VERSION ""

NS_ :

BS_:

BU_:

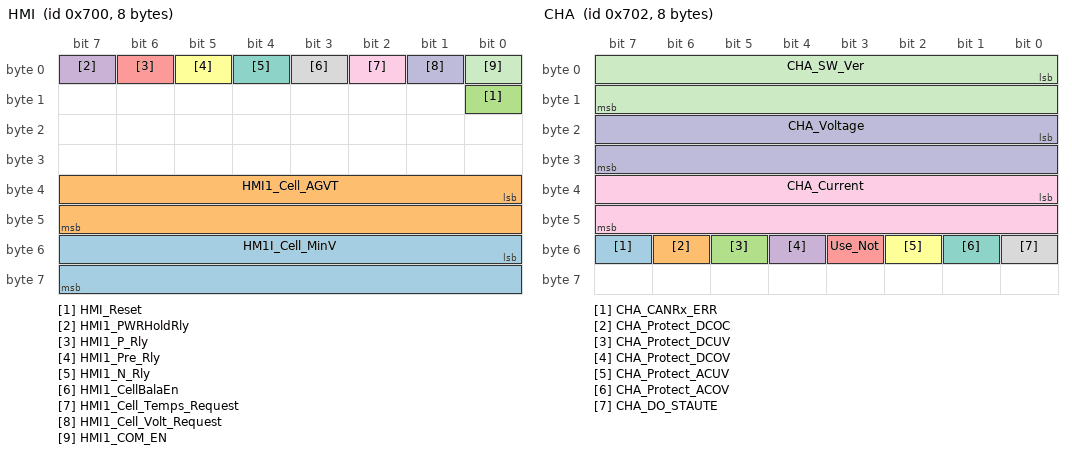
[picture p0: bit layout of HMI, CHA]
BO_ 1792 HMI: 8 Vector__XXX
 SG_ HM1I_Cell_MinV : 48|16@1+ (0.001,0.0) [0.0|4.5] "V" Vector__XXX
 SG_ HMI1_Cell_AGVT : 32|16@1+ (0.1,0.0) [-30.0|100.0] "deg" Vector__XXX
 SG_ HMI_Reset : 8|1@1+ (1.0,0.0) [0.0|1.0] "F" Vector__XXX
 SG_ HMI1_PWRHoldRly : 7|1@1+ (1.0,0.0) [0.0|1.0] "F" Vector__XXX
 SG_ HMI1_P_Rly : 6|1@1+ (1.0,0.0) [0.0|1.0] "F" Vector__XXX
 SG_ HMI1_Pre_Rly : 5|1@1+ (1.0,0.0) [0.0|1.0] "F" Vector__XXX
 SG_ HMI1_N_Rly : 4|1@1+ (1.0,0.0) [0.0|1.0] "F" Vector__XXX
 SG_ HMI1_CellBalaEn : 3|1@1+ (1.0,0.0) [0.0|1.0] "F" Vector__XXX
 SG_ HMI1_Cell_Temps_Request : 2|1@1+ (1.0,0.0) [0.0|1.0] "F" Vector__XXX
 SG_ HMI1_Cell_Volt_Request : 1|1@1+ (1.0,0.0) [0.0|1.0] "F" Vector__XXX
 SG_ HMI1_COM_EN : 0|1@1+ (1.0,0.0) [0.0|1.0] "F" Vector__XXX

BO_ 1794 CHA: 8 Vector__XXX
 SG_ CHA_CANRx_ERR : 55|1@1+ (1.0,0.0) [0.0|1.0] "F" Vector__XXX
 SG_ CHA_Protect_DCOC : 54|1@1+ (1.0,0.0) [0.0|1.0] "F" Vector__XXX
 SG_ CHA_Protect_DCUV : 53|1@1+ (1.0,0.0) [0.0|1.0] "F" Vector__XXX
 SG_ CHA_Protect_DCOV : 52|1@1+ (1.0,0.0) [0.0|1.0] "F" Vector__XXX
 SG_ Use_Not : 51|1@1+ (1.0,0.0) [0.0|1.0] "F" Vector__XXX
 SG_ CHA_Protect_ACUV : 50|1@1+ (1.0,0.0) [0.0|1.0] "F" Vector__XXX
 SG_ CHA_Protect_ACOV : 49|1@1+ (1.0,0.0) [0.0|1.0] "F" Vector__XXX
 SG_ CHA_DO_STAUTE : 48|1@1+ (1.0,0.0) [0.0|1.0] "F" Vector__XXX
 SG_ CHA_Current : 32|16@1- (0.1,0.0) [0.0|100.0] "A" Vector__XXX
 SG_ CHA_Voltage : 16|16@1+ (0.1,0.0) [40.0|100.0] "V" Vector__XXX
 SG_ CHA_SW_Ver : 0|16@1+ (0.1,0.0) [1.0|99.0] "VER" Vector__XXX

BO_ 1536 VCU_RE: 8 Vector__XXX
 SG_ VCU_BSAHldShutdown : 9|1@1+ (1.0,0.0) [0.0|1.0] "F" Vector__XXX
 SG_ VCU_BSAReset : 8|1@1+ (1.0,0.0) [0.0|1.0] "F" Vector__XXX

BO_ 812 CT_Sensor: 8 Sender
 SG_ CT_Sensor : 0|16@1+ (0.1,0.0) [-500.0|500.0] "A" Vector__XXX

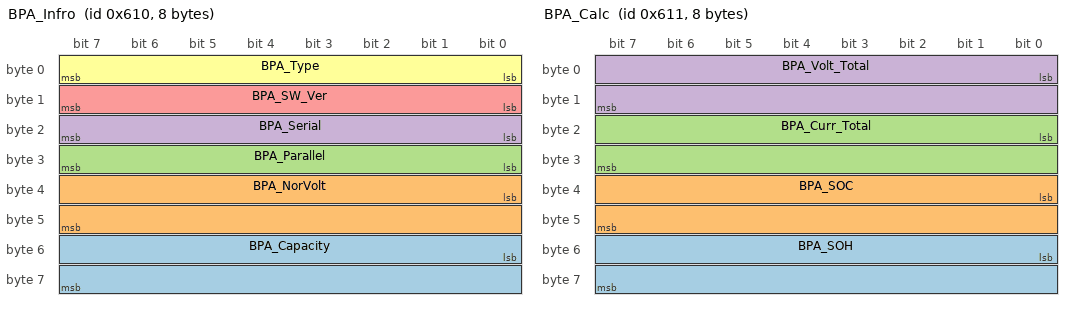
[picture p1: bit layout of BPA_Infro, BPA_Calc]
BO_ 1552 BPA_Infro: 8 Vector__XXX
 SG_ BPA_Capacity : 48|16@1+ (0.1,0.0) [0.0|500.0] "Ah" Vector__XXX
 SG_ BPA_NorVolt : 32|16@1+ (0.1,0.0) [0.0|900.0] "V" Vector__XXX
 SG_ BPA_Parallel : 24|8@1+ (1.0,0.0) [0.0|255.0] "P" Vector__XXX
 SG_ BPA_Serial : 16|8@1+ (1.0,0.0) [0.0|255.0] "S" Vector__XXX
 SG_ BPA_SW_Ver : 8|8@1+ (1.0,0.0) [0.0|255.0] "VER" Vector__XXX
 SG_ BPA_Type : 0|8@1+ (1.0,0.0) [0.0|255.0] "Type" Vector__XXX

BO_ 1553 BPA_Calc: 8 Vector__XXX
 SG_ BPA_SOH : 48|16@1+ (0.1,0.0) [0.0|100.0] "%" Vector__XXX
 SG_ BPA_SOC : 32|16@1+ (0.1,0.0) [0.0|100.0] "%" Vector__XXX
 SG_ BPA_Curr_Total : 16|16@1+ (0.1,0.0) [-500.0|500.0] "A" Vector__XXX
 SG_ BPA_Volt_Total : 0|16@1+ (0.1,0.0) [0.0|900.0] "V" Vector__XXX

BO_ 1554 BPA_State: 8 Vector__XXX
 SG_ Sys_HMIBalanceMode : 63|1@1+ (1.0,0.0) [0.0|1.0] "F" Vector__XXX
 SG_ Sys_HMICOMMode : 62|1@1+ (1.0,0.0) [0.0|1.0] "F" Vector__XXX
 SG_ Sys_IMDRegErr : 61|1@1+ (1.0,0.0) [0.0|1.0] "F" Vector__XXX
 SG_ Sys_ISOSPICOMERR : 60|1@1+ (1.0,0.0) [0.0|1.0] "F" Vector__XXX
 SG_ Sys_CANCOMERR : 59|1@1+ (1.0,0.0) [0.0|1.0] "F" Vector__XXX
 SG_ Sys_RlyERR : 58|1@1+ (1.0,0.0) [0.0|1.0] "F" Vector__XXX
 SG_ Sys_MSDERR : 57|1@1+ (1.0,0.0) [0.0|1.0] "F" Vector__XXX
 SG_ Sys_CellTempsOk : 56|1@1+ (1.0,0.0) [0.0|1.0] "F" Vector__XXX
 SG_ Sys_CellVoltOk : 55|1@1+ (1.0,0.0) [0.0|1.0] "F" Vector__XXX
 SG_ Sys_PwrHoldRlyDOStatus : 54|1@1+ (1.0,0.0) [0.0|1.0] "F" Vector__XXX
 SG_ Sys_PreRlyDOStatus : 53|1@1+ (1.0,0.0) [0.0|1.0] "F" Vector__XXX
 SG_ Sys_PRlyDOStatus : 52|1@1+ (1.0,0.0) [0.0|1.0] "F" Vector__XXX
 SG_ Sys_NRlyDOStatus : 51|1@1+ (1.0,0.0) [0.0|1.0] "F" Vector__XXX
 SG_ Sys_Prtct : 50|1@1+ (1.0,0.0) [0.0|1.0] "F" Vector__XXX
 SG_ Sys_Fault : 49|1@1+ (1.0,0.0) [0.0|1.0] "F" Vector__XXX
 SG_ Sys_Aalarm : 48|1@1+ (1.0,0.0) [0.0|1.0] "F" Vector__XXX
 SG_ Sys_DisCharMode : 47|1@1+ (1.0,0.0) [0.0|1.0] "F" Vector__XXX
 SG_ Sys_BalanceEn : 46|1@1+ (1.0,0.0) [0.0|1.0] "F" Vector__XXX
 SG_ Sys_BalaMode : 45|1@1+ (1.0,0.0) [0.0|1.0] "F" Vector__XXX
 SG_ Sys_SocMode : 44|1@1+ (1.0,0.0) [0.0|1.0] "F" Vector__XXX
 SG_ ChargerWakeUp : 43|1@1+ (1.0,0.0) [0.0|1.0] "F" Vector__XXX
 SG_ VCURlyWakeUp : 42|1@1+ (1.0,0.0) [0.0|1.0] "F" Vector__XXX
 SG_ CANCOMEnable : 41|1@1+ (1.0,0.0) [0.0|1.0] "F" Vector__XXX
 SG_ Sys_INITOK : 40|1@1+ (1.0,0.0) [0.0|1.0] "F" Vector__XXX
 SG_ Sys_SocSeqState : 38|2@1+ (1.0,0.0) [0.0|3.0] "s" Vector__XXX
 SG_ SyS_RlySeqState : 35|3@1+ (1.0,0.0) [0.0|7.0] "S" Vector__XXX
 SG_ Sys_SysSeqState : 32|3@1+ (1.0,0.0) [0.0|7.0] "S" Vector__XXX
 SG_ BPA_ChargerEn : 21|1@1+ (1.0,0.0) [0.0|1.0] "F" Vector__XXX
 SG_ BPA_MSD_AUX : 20|1@1+ (1.0,0.0) [0.0|1.0] "F" Vector__XXX
 SG_ BPA_PreChar_Rly : 19|1@1+ (1.0,0.0) [0.0|1.0] "F" Vector__XXX
 SG_ BPA_Pos_Rly : 18|1@1+ (1.0,0.0) [0.0|1.0] "F" Vector__XXX
 SG_ BPA_Neg_Rly : 17|1@1+ (1.0,0.0) [0.0|1.0] "F" Vector__XXX
 SG_ BPA_Balance : 16|1@1+ (1.0,0.0) [0.0|1.0] "F" Vector__XXX
 SG_ BPA_Protect_Status : 8|8@1+ (1.0,0.0) [0.0|5.0] "P" Vector__XXX
 SG_ BPA_Divice_Status : 0|8@1+ (1.0,0.0) [0.0|5.0] "S" Vector__XXX

BO_ 1555 BPA_ProtectState: 8 Vector__XXX
 SG_ BPA_Prtct_Charger_PwrErr : 53|1@1+ (1.0,0.0) [0.0|1.0] "F" Vector__XXX
 SG_ BPA_Prtct_Discharger_PwrErr : 52|1@1+ (1.0,0.0) [0.0|1.0] "F" Vector__XXX
 SG_ BPA_Prtct_CTCom_Err : 51|1@1+ (1.0,0.0) [0.0|1.0] "F" Vector__XXX
 SG_ BPA_Prtct_CharCom_Err : 50|1@1+ (1.0,0.0) [0.0|1.0] "F" Vector__XXX
 SG_ BPA_Prtct_VCUCom_Err : 49|1@1+ (1.0,0.0) [0.0|1.0] "F" Vector__XXX
 SG_ BPA_Prtct_ISOSPI_Err : 48|1@1+ (1.0,0.0) [0.0|1.0] "F" Vector__XXX
 SG_ BPA_Prtct_ISORESIS_Err : 47|1@1+ (1.0,0.0) [0.0|1.0] "F" Vector__XXX
 SG_ BPA_Prtct_MSD_Err : 46|1@1+ (1.0,0.0) [0.0|1.0] "F" Vector__XXX
 SG_ BPA_Prtct_Rly_Err : 45|1@1+ (1.0,0.0) [0.0|1.0] "F" Vector__XXX
 SG_ BPA_Prtct_Cell_UnbalT : 44|1@1+ (1.0,0.0) [0.0|1.0] "F" Vector__XXX
 SG_ BPA_Prtct_Cell_UT : 43|1@1+ (1.0,0.0) [0.0|1.0] "F" Vector__XXX
 SG_ BPA_Prtct_Cell_OT : 42|1@1+ (1.0,0.0) [0.0|1.0] "F" Vector__XXX
 SG_ BPA_Prtct_Cell_UnbalV : 41|1@1+ (1.0,0.0) [0.0|1.0] "F" Vector__XXX
 SG_ BPA_Prtct_Cell_UV : 40|1@1+ (1.0,0.0) [0.0|1.0] "F" Vector__XXX
 SG_ BPA_Prtct_Cell_OV : 39|1@1+ (1.0,0.0) [0.0|1.0] "F" Vector__XXX
 SG_ BPA_Prtct_UT : 38|1@1+ (1.0,0.0) [0.0|1.0] "F" Vector__XXX
 SG_ BPA_Prtct_OT : 37|1@1+ (1.0,0.0) [0.0|1.0] "F" Vector__XXX
 SG_ BPA_Prtct_UV : 36|1@1+ (1.0,0.0) [0.0|1.0] "F" Vector__XXX
 SG_ BPA_Prtct_OV : 35|1@1+ (1.0,0.0) [0.0|1.0] "F" Vector__XXX
 SG_ BPA_Prtct_SOC_Under : 34|1@1+ (1.0,0.0) [0.0|1.0] "F" Vector__XXX
 SG_ BPA_Prtct_SOC_Over : 33|1@1+ (1.0,0.0) [0.0|1.0] "F" Vector__XXX
 SG_ BPA_Prtct_OC : 32|1@1+ (1.0,0.0) [0.0|1.0] "" Vector__XXX
 SG_ BPA_FLT_Charger_UnBPAWR : 30|1@1+ (1.0,0.0) [0.0|1.0] "F" Vector__XXX
 SG_ BPA_FLT_Discharger_UnBPAWR : 29|1@1+ (1.0,0.0) [0.0|1.0] "F" Vector__XXX
 SG_ BSA_FLT_Cell_UnbalT : 28|1@1+ (1.0,0.0) [0.0|1.0] "F" Vector__XXX
 SG_ BPA_FLT_Cell_UT : 27|1@1+ (1.0,0.0) [0.0|1.0] "F" Vector__XXX
 SG_ BPA_FLT_Cell_OT : 26|1@1+ (1.0,0.0) [0.0|1.0] "F" Vector__XXX
 SG_ BPA_FLT_Cell_UnbalV : 25|1@1+ (1.0,0.0) [0.0|1.0] "F" Vector__XXX
 SG_ BPA_FLT_Cell_UV : 24|1@1+ (1.0,0.0) [0.0|1.0] "F" Vector__XXX
 SG_ BPA_FLT_Cell_OV : 23|1@1+ (1.0,0.0) [0.0|1.0] "F" Vector__XXX
 SG_ BPA_FLT_UT : 22|1@1+ (1.0,0.0) [0.0|1.0] "F" Vector__XXX
 SG_ BPA_FLT_OT : 21|1@1+ (1.0,0.0) [0.0|1.0] "F" Vector__XXX
 SG_ BPA_FLT_UV : 20|1@1+ (1.0,0.0) [0.0|1.0] "F" Vector__XXX
 SG_ BPA_FLT_OV : 19|1@1+ (1.0,0.0) [0.0|1.0] "F" Vector__XXX
 SG_ BPA_FLT_SOC_Under : 18|1@1+ (1.0,0.0) [0.0|1.0] "F" Vector__XXX
 SG_ BPA_FLT_SOC_Over : 17|1@1+ (1.0,0.0) [0.0|1.0] "F" Vector__XXX
 SG_ BPA_FLT_OC : 16|1@1+ (1.0,0.0) [0.0|1.0] "F" Vector__XXX
 SG_ BPA_Wn_Charger_UnBPAWR : 14|1@1+ (1.0,0.0) [0.0|1.0] "F" Vector__XXX
 SG_ BPA_Wn_Discharger_UnBPAWR : 13|1@1+ (1.0,0.0) [0.0|1.0] "F" Vector__XXX
 SG_ BSA_Wn_Cell_UnbalT : 12|1@1+ (1.0,0.0) [0.0|1.0] "F" Vector__XXX
 SG_ BPA_Wn_Cell_UT : 11|1@1+ (1.0,0.0) [0.0|1.0] "F" Vector__XXX
 SG_ BPA_Wn_Cell_OT : 10|1@1+ (1.0,0.0) [0.0|1.0] "F" Vector__XXX
 SG_ BPA_Wn_Cell_UnbalV : 9|1@1+ (1.0,0.0) [0.0|1.0] "F" Vector__XXX
 SG_ BPA_Wn_Cell_UV : 8|1@1+ (1.0,0.0) [0.0|1.0] "F" Vector__XXX
 SG_ BPA_Wn_Cell_OV : 7|1@1+ (1.0,0.0) [0.0|1.0] "F" Vector__XXX
 SG_ BPA_Wn_UT : 6|1@1+ (1.0,0.0) [0.0|1.0] "F" Vector__XXX
 SG_ BPA_Wn_OT : 5|1@1+ (1.0,0.0) [0.0|1.0] "F" Vector__XXX
 SG_ BPA_Wn_UV : 4|1@1+ (1.0,0.0) [0.0|1.0] "F" Vector__XXX
 SG_ BPA_Wn_OV : 3|1@1+ (1.0,0.0) [0.0|1.0] "F" Vector__XXX
 SG_ BPA_Wn_SOC_Under : 2|1@1+ (1.0,0.0) [0.0|1.0] "F" Vector__XXX
 SG_ BPA_Wn_SOC_Over : 1|1@1+ (1.0,0.0) [0.0|1.0] "F" Vector__XXX
 SG_ BPA_Wn_OC : 0|1@1+ (1.0,0.0) [0.0|1.0] "F" Vector__XXX

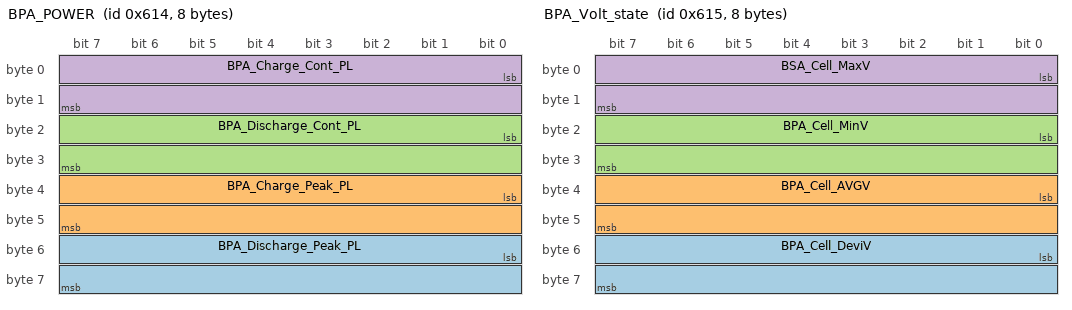
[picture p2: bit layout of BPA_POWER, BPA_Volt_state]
BO_ 1556 BPA_POWER: 8 Vector__XXX
 SG_ BPA_Discharge_Peak_PL : 48|16@1+ (0.1,0.0) [0.0|20.0] "kW" Vector__XXX
 SG_ BPA_Charge_Peak_PL : 32|16@1+ (0.1,0.0) [0.0|20.0] "kW" Vector__XXX
 SG_ BPA_Discharge_Cont_PL : 16|16@1+ (0.1,0.0) [0.0|20.0] "kW" Vector__XXX
 SG_ BPA_Charge_Cont_PL : 0|16@1+ (0.1,0.0) [0.0|20.0] "kW" Vector__XXX

BO_ 1557 BPA_Volt_state: 8 Vector__XXX
 SG_ BPA_Cell_DeviV : 48|16@1+ (1.0,0.0) [0.0|1000.0] "mV" Vector__XXX
 SG_ BPA_Cell_AVGV : 32|16@1+ (0.001,0.0) [0.0|4.5] "V" Vector__XXX
 SG_ BPA_Cell_MinV : 16|16@1+ (0.001,0.0) [0.0|4.5] "V" Vector__XXX
 SG_ BSA_Cell_MaxV : 0|16@1+ (0.001,0.0) [0.0|4.5] "V" Vector__XXX

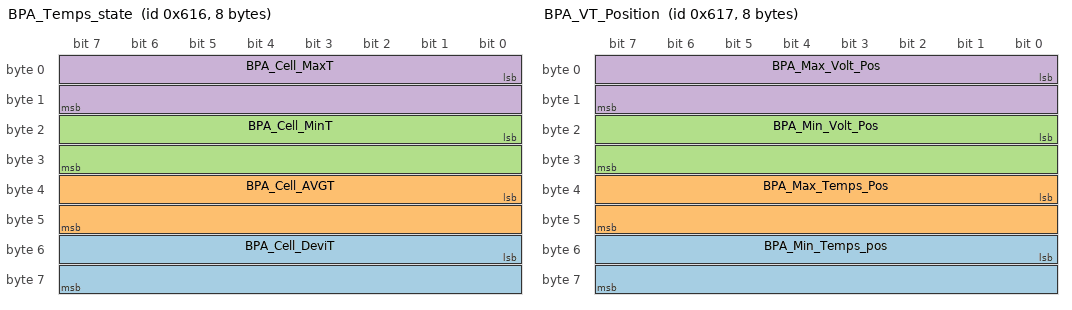
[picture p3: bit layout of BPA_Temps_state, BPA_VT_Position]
BO_ 1558 BPA_Temps_state: 8 Vector__XXX
 SG_ BPA_Cell_DeviT : 48|16@1+ (0.1,0.0) [0.0|100.0] "deg" Vector__XXX
 SG_ BPA_Cell_AVGT : 32|16@1+ (0.1,0.0) [-30.0|100.0] "deg" Vector__XXX
 SG_ BPA_Cell_MinT : 16|16@1+ (0.1,0.0) [-30.0|100.0] "deg" Vector__XXX
 SG_ BPA_Cell_MaxT : 0|16@1+ (0.1,0.0) [-30.0|100.0] "deg" Vector__XXX

BO_ 1559 BPA_VT_Position: 8 Vector__XXX
 SG_ BPA_Min_Temps_pos : 48|16@1+ (1.0,0.0) [0.0|200.0] "Pos" Vector__XXX
 SG_ BPA_Max_Temps_Pos : 32|16@1+ (1.0,0.0) [0.0|200.0] "Pos" Vector__XXX
 SG_ BPA_Min_Volt_Pos : 16|16@1+ (1.0,0.0) [0.0|200.0] "Pos" Vector__XXX
 SG_ BPA_Max_Volt_Pos : 0|16@1+ (1.0,0.0) [0.0|200.0] "Pos" Vector__XXX

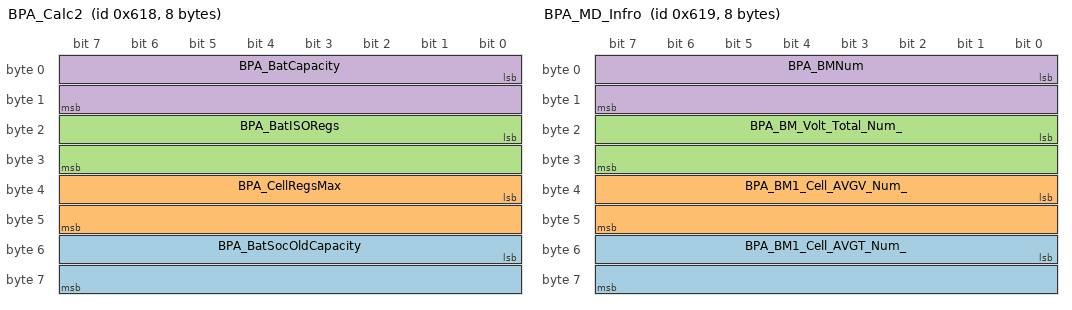
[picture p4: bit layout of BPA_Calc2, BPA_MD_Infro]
BO_ 1560 BPA_Calc2: 8 Vector__XXX
 SG_ BPA_BatSocOldCapacity : 48|16@1+ (0.1,0.0) [0.0|500.0] "Ah" Vector__XXX
 SG_ BPA_CellRegsMax : 32|16@1+ (0.1,0.0) [0.0|100.0] "mOhm" Vector__XXX
 SG_ BPA_BatISORegs : 16|16@1+ (0.1,0.0) [0.0|1000.0] "Mohm" Vector__XXX
 SG_ BPA_BatCapacity : 0|16@1+ (0.1,0.0) [-500.0|500.0] "Ah" Vector__XXX

BO_ 1561 BPA_MD_Infro: 8 Vector__XXX
 SG_ BPA_BM1_Cell_AVGT_Num_ : 48|16@1+ (0.1,0.0) [-30.0|100.0] "deg" Vector__XXX
 SG_ BPA_BM1_Cell_AVGV_Num_ : 32|16@1+ (0.001,0.0) [0.0|4.5] "V" Vector__XXX
 SG_ BPA_BM_Volt_Total_Num_ : 16|16@1+ (0.1,0.0) [0.0|100.0] "V" Vector__XXX
 SG_ BPA_BMNum : 0|16@1+ (0.1,0.0) [0.0|32.0] "V" Vector__XXX

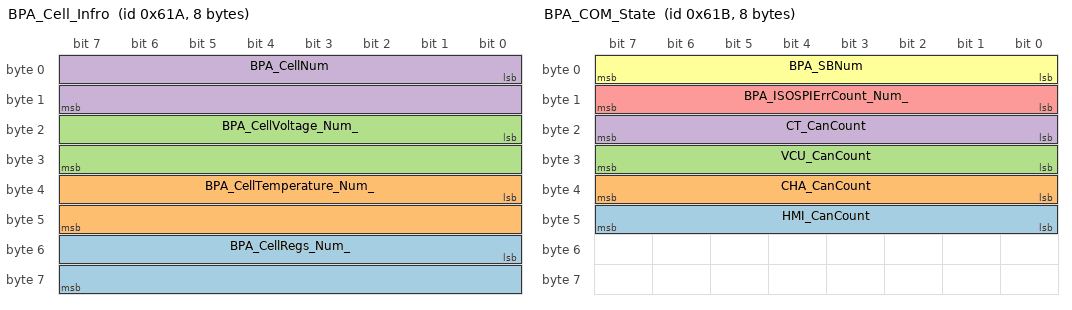
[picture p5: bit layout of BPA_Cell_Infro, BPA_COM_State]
BO_ 1562 BPA_Cell_Infro: 8 Vector__XXX
 SG_ BPA_CellRegs_Num_ : 48|16@1+ (0.1,0.0) [0.0|100.0] "mhom" Vector__XXX
 SG_ BPA_CellTemperature_Num_ : 32|16@1+ (0.1,0.0) [-30.0|100.0] "deg" Vector__XXX
 SG_ BPA_CellVoltage_Num_ : 16|16@1+ (0.001,0.0) [0.0|4.5] "V" Vector__XXX
 SG_ BPA_CellNum : 0|16@1+ (1.0,0.0) [0.0|400.0] "Num" Vector__XXX

BO_ 1563 BPA_COM_State: 8 Vector__XXX
 SG_ HMI_CanCount : 40|8@1+ (1.0,0.0) [0.0|250.0] "Cnt" Vector__XXX
 SG_ CHA_CanCount : 32|8@1+ (1.0,0.0) [0.0|250.0] "Cnt" Vector__XXX
 SG_ VCU_CanCount : 24|8@1+ (1.0,0.0) [0.0|250.0] "Cnt" Vector__XXX
 SG_ CT_CanCount : 16|8@1+ (1.0,0.0) [0.0|250.0] "Cnt" Vector__XXX
 SG_ BPA_ISOSPIErrCount_Num_ : 8|8@1+ (1.0,0.0) [0.0|250.0] "Cnt" Vector__XXX
 SG_ BPA_SBNum : 0|8@1+ (1.0,0.0) [0.0|30.0] "Num" Vector__XXX

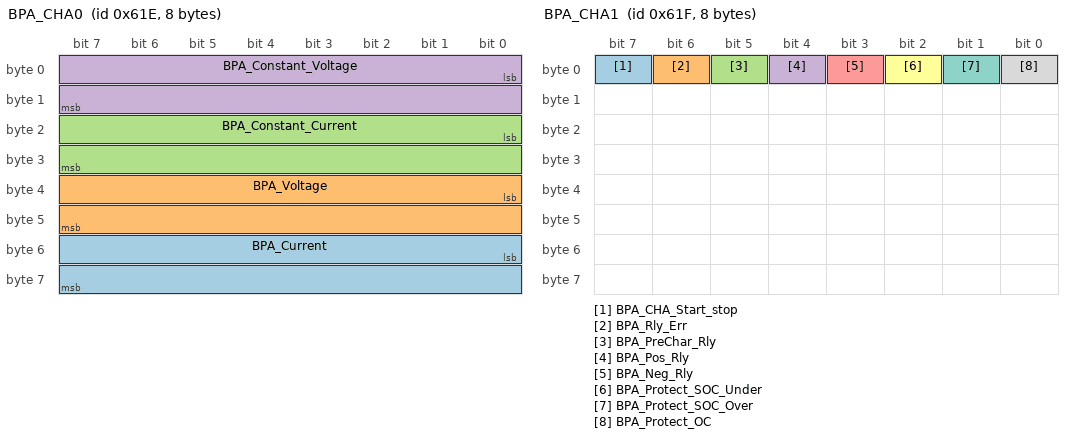
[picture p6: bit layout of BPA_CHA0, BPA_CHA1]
BO_ 1566 BPA_CHA0: 8 Vector__XXX
 SG_ BPA_Current : 48|16@1- (0.1,0.0) [0.0|100.0] "A" Vector__XXX
 SG_ BPA_Voltage : 32|16@1+ (0.1,0.0) [0.0|100.0] "v" Vector__XXX
 SG_ BPA_Constant_Current : 16|16@1- (0.1,0.0) [5.0|100.0] "A" Vector__XXX
 SG_ BPA_Constant_Voltage : 0|16@1+ (0.1,0.0) [40.0|100.0] "V" Vector__XXX

BO_ 1567 BPA_CHA1: 8 Vector__XXX
 SG_ BPA_CHA_Start_stop : 7|1@1+ (1.0,0.0) [0.0|1.0] "F" Vector__XXX
 SG_ BPA_Rly_Err : 6|1@1+ (1.0,0.0) [0.0|1.0] "F" Vector__XXX
 SG_ BPA_PreChar_Rly : 5|1@1+ (1.0,0.0) [0.0|1.0] "F" Vector__XXX
 SG_ BPA_Pos_Rly : 4|1@1+ (1.0,0.0) [0.0|1.0] "F" Vector__XXX
 SG_ BPA_Neg_Rly : 3|1@1+ (1.0,0.0) [0.0|1.0] "F" Vector__XXX
 SG_ BPA_Protect_SOC_Under : 2|1@1+ (1.0,0.0) [0.0|1.0] "F" Vector__XXX
 SG_ BPA_Protect_SOC_Over : 1|1@1+ (1.0,0.0) [0.0|1.0] "F" Vector__XXX
 SG_ BPA_Protect_OC : 0|1@1+ (1.0,0.0) [0.0|1.0] "F" Vector__XXX

BO_TX_BU_ 812 : Sender,GINT 검토 의견;

CM_ SG_ 1792 HM1I_Cell_MinV "VCU CAN 통신 분리 된 상태에서
관리자가 BMS에게 강제로 셀 전압 균일화를 요청";
CM_ SG_ 1792 HMI1_Cell_AGVT "VCU CAN 통신 분리 된 상태에서
관리자가 BMS에게 셀 온도 데이터를 요청 ";
CM_ SG_ 1792 HMI_Reset "0X00=No Actioen
0x01=HMIReset";
CM_ SG_ 1792 HMI1_PWRHoldRly "0X00=Off;
0x01=On;";
CM_ SG_ 1792 HMI1_P_Rly "0X00=Off;
0x01=On;";
CM_ SG_ 1792 HMI1_Pre_Rly "0X00=Off;
0x01=On;";
CM_ SG_ 1792 HMI1_N_Rly "0X00=Off;
0x01=On;";
CM_ SG_ 1792 HMI1_CellBalaEn "0X00=No Actioen
0x01=HMIBalace";
CM_ SG_ 1792 HMI1_Cell_Temps_Request "VCU CAN 통신 분리 된 상태에서
관리자가 BMS에게 셀 전압 데이터를 요청 ";
CM_ SG_ 1792 HMI1_Cell_Volt_Request "VCU CAN 통신 분리 된 상태에서
관리자가 Battery System에게 셀 전압 데이터 요청 ";
CM_ SG_ 1792 HMI1_COM_EN "VCU CAN 통신 분리 된 상태에서 관리자가 Battery System 상태를 모니터링 하기 위한 모드 설정
0x0=No Action;
0x1=HMImODE;";
CM_ SG_ 1794 CHA_CANRx_ERR "0x0=NoAction
0x1= 배터리 시스템 - 충전기 간 CAN Communication Error";
CM_ SG_ 1794 CHA_Protect_DCOC "0x0=NoAction0;
0x1=BATE_UV;";
CM_ SG_ 1794 CHA_Protect_DCUV "0x0=NoAction; 
0x1=BATE_UV;";
CM_ SG_ 1794 CHA_Protect_DCOV "0x0=NoAction;
0x1=BATE_OV;";
CM_ SG_ 1794 Use_Not "Use Not";
CM_ SG_ 1794 CHA_Protect_ACUV "0x0=No Action, 
0x1=AC_UV";
CM_ SG_ 1794 CHA_Protect_ACOV "0x0=No Action, 
0x1=AC_OV;";
CM_ SG_ 1794 CHA_DO_STAUTE "0x0=Rly_Off;
0x1=Rly_On;";
CM_ SG_ 1794 CHA_Current "충전기에서 측정하고 배터리 전류 ";
CM_ SG_ 1794 CHA_Voltage "충전기에서 측정하고 배터리 전압 ";
CM_ SG_ 1794 CHA_SW_Ver "충전기 프로그램 버전 ";
CM_ SG_ 1536 VCU_BSAHldShutdown "킬 스위치 off 일 때 VCU측에서 ROFF이후 VCU 가 BAT 파워 릴레이 OFF명령
0x0=NoAction;
0x1=BPARly_OFF;";
CM_ SG_ 1536 VCU_BSAReset "VCU 가 BAT Protect 상태를 Reset 
0x0=NoAction
0x1=Reset;";
CM_ SG_ 812 CT_Sensor "유첨파일 참조";
CM_ SG_ 1552 BPA_Capacity "default(Battery System 전지용량), 460Ah(DoD 100%)";
CM_ SG_ 1552 BPA_NorVolt "default(Battery System 전지전압), 48V";
CM_ SG_ 1552 BPA_Parallel "default(Battery System 전지 병렬구성), 2";
CM_ SG_ 1552 BPA_Serial "default(Battery System 전지 직렬구성), 15";
CM_ SG_ 1552 BPA_SW_Ver "default(소프트웨어정보), 10";
CM_ SG_ 1552 BPA_Type "default(제품정보), 03";
CM_ SG_ 1553 BPA_SOH "Battery System 전지 상태값";
CM_ SG_ 1553 BPA_SOC "Battery System 충전량";
CM_ SG_ 1553 BPA_Curr_Total "Battery System 전류값";
CM_ SG_ 1553 BPA_Volt_Total "Battery System 전압값";
CM_ SG_ 1554 Sys_HMIBalanceMode "0x0 : Off;
0x1 : Ok";
CM_ SG_ 1554 Sys_HMICOMMode "0x0 : Off;
0x1 : Ok";
CM_ SG_ 1554 Sys_IMDRegErr "0x0 : Nor;
0x1 : Protect";
CM_ SG_ 1554 Sys_ISOSPICOMERR "0x0 : Nor;
0x1 : Protect";
CM_ SG_ 1554 Sys_CANCOMERR "0x0 : Nor;
0x1 : Protect";
CM_ SG_ 1554 Sys_RlyERR "0x0 : Nor;
0x1 : Protect";
CM_ SG_ 1554 Sys_MSDERR "0x0 : Nor;
0x1 : Protect";
CM_ SG_ 1554 Sys_CellTempsOk "0x0 : Off;
0x1 : Ok";
CM_ SG_ 1554 Sys_CellVoltOk "0x0 : Off;
0x1 : Ok";
CM_ SG_ 1554 Sys_PwrHoldRlyDOStatus "0x0 : Off
0x1 : On";
CM_ SG_ 1554 Sys_PreRlyDOStatus "0x0 : Off
0x1 : On";
CM_ SG_ 1554 Sys_PRlyDOStatus "0x0 : Off
0x1 : On";
CM_ SG_ 1554 Sys_NRlyDOStatus "0x0 : Off
0x1 : On";
CM_ SG_ 1554 Sys_Prtct "0x0 : Nor;
0x1 : Protect";
CM_ SG_ 1554 Sys_Fault "0x0 : Nor;
0x1 : Fault";
CM_ SG_ 1554 Sys_Aalarm "0x0 : Nor;
0x1 : Alarm";
CM_ SG_ 1554 Sys_BalaMode "0x0 : Char
0x1 : DisChar";
CM_ SG_ 1554 Sys_SocMode "0x0 : Off
0x1 : On";
CM_ SG_ 1554 ChargerWakeUp "0x0 : Disable
0x1 : Enable";
CM_ SG_ 1554 VCURlyWakeUp "0x0 : Disable
0x1 : Enable";
CM_ SG_ 1554 Sys_INITOK "0x0 : Off;
0x1 : Ok";
CM_ SG_ 1554 Sys_SocSeqState "0x0: SOC_STATE_IDLE,
0x1: SOC_STATE_RUNNING,
0x2: SOC_STATE_Save,
0x3: SOC_STATE_CLEAR";
CM_ SG_ 1554 SyS_RlySeqState "0x0 : PrtctRly_INIT;
0x1 : PrtctRly_STANDBY;
0x2 : PrtctRly_Ready;
0x3 : PrtctRly_RuningON;
0x4 : PrtctRly_RuningOFF;
0x5 : PrtctRly_ProtectpOFF;
0x6 : PrtctRly_RLYProtect;
0x7 : PrtctRly_CLEAR;";
CM_ SG_ 1554 Sys_SysSeqState "0x0 : INIT;
0x1 : STANDBY;
0x2 : READY;
0x3 : RUNING;
0x4 : ChargerStop
0x5 : PROTECTER;
0x6 : DATALOG;
0x7 : MANUALMode;";
CM_ SG_ 1554 BPA_ChargerEn "0x00 : DisCharEnable;
0x01 : CharEnable;";
CM_ SG_ 1554 BPA_MSD_AUX "미적용 ";
CM_ SG_ 1554 BPA_PreChar_Rly "0x0=Rly_Off;
0x1=Rly_On;";
CM_ SG_ 1554 BPA_Pos_Rly "0x0=Rly_Off;
0x1=Rly_On;";
CM_ SG_ 1554 BPA_Neg_Rly "0x0=Rly_Off;
0x1=Rly_On;";
CM_ SG_ 1554 BPA_Balance "0x00 : OFF
0x01 : ON";
CM_ SG_ 1554 BPA_Protect_Status "0x00 : Nor;
0x01 : waring;
0x02 : Fault; //차량에서 자체적으로 판단 배터리 보호 
0x03 : Protect; // 배터리 내에서 자체적으로 판단 배터리 보호 및 릴레이 off";
CM_ SG_ 1554 BPA_Divice_Status "0x00 : Init
0x01 : standby
0x02 : Charger mode
0x03 : Dischager mode ";
CM_ SG_ 1555 BPA_Prtct_Charger_PwrErr "0x0 : Nor;
0x1 : Protect";
CM_ SG_ 1555 BPA_Prtct_Discharger_PwrErr "0x0 : Nor;
0x1 : Protect";
CM_ SG_ 1555 BPA_Prtct_CTCom_Err "0x0 : Nor;
0x1 : Protect";
CM_ SG_ 1555 BPA_Prtct_CharCom_Err "0x0 : Nor;
0x1 : Protect";
CM_ SG_ 1555 BPA_Prtct_VCUCom_Err "0x0 : Nor;
0x1 : Protect";
CM_ SG_ 1555 BPA_Prtct_ISOSPI_Err "0x0 : Nor;
0x1 : Protect";
CM_ SG_ 1555 BPA_Prtct_ISORESIS_Err "0x0 : Nor;
0x1 : Protect";
CM_ SG_ 1555 BPA_Prtct_MSD_Err "0x0 : Nor;
0x1 : Protect";
CM_ SG_ 1555 BPA_Prtct_Rly_Err "0x0 : Nor;
0x1 : Protect";
CM_ SG_ 1555 BPA_Prtct_Cell_UnbalT "0x0 : Nor;
0x1 : Protect";
CM_ SG_ 1555 BPA_Prtct_Cell_UT "0x0 : Nor;
0x1 : Protect";
CM_ SG_ 1555 BPA_Prtct_Cell_OT "0x0 : Nor;
0x1 : Protect";
CM_ SG_ 1555 BPA_Prtct_Cell_UnbalV "0x0 : Nor;
0x1 : Protect";
CM_ SG_ 1555 BPA_Prtct_Cell_UV "0x0 : Nor;
0x1 : Protect";
CM_ SG_ 1555 BPA_Prtct_Cell_OV "0x0 : Nor;
0x1 : Protect";
CM_ SG_ 1555 BPA_Prtct_UT "0x0 : Nor;
0x1 : Protect";
CM_ SG_ 1555 BPA_Prtct_OT "0x0 : Nor;
0x1 : Protect";
CM_ SG_ 1555 BPA_Prtct_UV "0x0 : Nor;
0x1 : Protect";
CM_ SG_ 1555 BPA_Prtct_OV "0x0 : Nor;
0x1 : Protect";
CM_ SG_ 1555 BPA_Prtct_SOC_Under "0x0 : Nor;
0x1 : Protect";
CM_ SG_ 1555 BPA_Prtct_SOC_Over "0x0 : Nor;
0x1 : Protect";
CM_ SG_ 1555 BPA_Prtct_OC "CAN ID = 0X612, BIT21 
BPA_ChargerEn=1 발생 경우에는 OC  발생 시에는 충전 시 과전류 발생
BPA_ChargerEn=0 발생 경우에는 OC  발생 시에는 방전 시 과전류 발생";
CM_ SG_ 1555 BPA_FLT_Charger_UnBPAWR "0x0 : Nor;
0x1 : Fault";
CM_ SG_ 1555 BPA_FLT_Discharger_UnBPAWR "0x0 : Nor;
0x1 : Fault";
CM_ SG_ 1555 BSA_FLT_Cell_UnbalT "0x0 : Nor;
0x1 : Fault";
CM_ SG_ 1555 BPA_FLT_Cell_UT "0x0 : Nor;
0x1 : Fault";
CM_ SG_ 1555 BPA_FLT_Cell_OT "0x0 : Nor;
0x1 : Fault";
CM_ SG_ 1555 BPA_FLT_Cell_UnbalV "0x0 : Nor;
0x1 : Fault";
CM_ SG_ 1555 BPA_FLT_Cell_UV "0x0 : Nor;
0x1 : Fault";
CM_ SG_ 1555 BPA_FLT_Cell_OV "0x0 : Nor;
0x1 : Fault";
CM_ SG_ 1555 BPA_FLT_UT "0x0 : Nor;
0x1 : Fault";
CM_ SG_ 1555 BPA_FLT_OT "0x0 : Nor;
0x1 : Fault";
CM_ SG_ 1555 BPA_FLT_UV "0x0 : Nor;
0x1 : Fault";
CM_ SG_ 1555 BPA_FLT_OV "0x0 : Nor;
0x1 : Fault";
CM_ SG_ 1555 BPA_FLT_SOC_Under "0x0 : Nor;
0x1 : Fault";
CM_ SG_ 1555 BPA_FLT_SOC_Over "0x0 : Nor;
0x1 : Fault";
CM_ SG_ 1555 BPA_FLT_OC "CAN ID = 0X612, BIT21 
BPA_ChargerEn=1 발생 경우에는 OC  발생 시에는 충전 시 과전류 발생
BPA_ChargerEn=0 발생 경우에는 OC  발생 시에는 방전 시 과전류 발생";
CM_ SG_ 1555 BPA_Wn_OC "CAN ID = 0X612, BIT21 
BPA_ChargerEn=1 발생 경우에는 OC  발생 시에는 충전 시 과전류 발생
BPA_ChargerEn=0 발생 경우에는 OC  발생 시에는 방전 시 과전류 발생";
CM_ SG_ 1556 BPA_Discharge_Peak_PL "Battery System Discharge Peak out Power limit";
CM_ SG_ 1556 BPA_Charge_Peak_PL "Battery System Charge Peak out Power limit";
CM_ SG_ 1556 BPA_Discharge_Cont_PL "Battery System Discharge continuity out Power limit";
CM_ SG_ 1556 BPA_Charge_Cont_PL "BATTERY System Charge continuity out Power limit";
CM_ SG_ 1557 BPA_Cell_DeviV "Battery System  Cell 전압편차값";
CM_ SG_ 1557 BPA_Cell_AVGV "Battery System Cell 평균전압값";
CM_ SG_ 1557 BPA_Cell_MinV "Battery System Cell 최저전압값";
CM_ SG_ 1557 BSA_Cell_MaxV "Battery System Cell 최대전압값";
CM_ SG_ 1558 BPA_Cell_DeviT "Battery System Cell 온도편차값";
CM_ SG_ 1558 BPA_Cell_AVGT "Battery System Cell 평균온도값";
CM_ SG_ 1558 BPA_Cell_MinT "Battery System Cell 최저온도값";
CM_ SG_ 1558 BPA_Cell_MaxT "Battery System Cell 최대온도값";
CM_ SG_ 1559 BPA_Min_Temps_pos "Battery System 최소온도값";
CM_ SG_ 1559 BPA_Max_Temps_Pos "Battery System 최대온도값";
CM_ SG_ 1559 BPA_Min_Volt_Pos "Battery System 최소전압값";
CM_ SG_ 1559 BPA_Max_Volt_Pos "Battery System 최대전압값";
CM_ SG_ 1560 BPA_BatSocOldCapacity "NVRAM 저장 중인 SOC ";
CM_ SG_ 1560 BPA_CellRegsMax "Battery System 단전지 내부저항 최대값";
CM_ SG_ 1560 BPA_BatISORegs "Battery System 절연저항";
CM_ SG_ 1560 BPA_BatCapacity "Battery System 전류적산";
CM_ SG_ 1561 BPA_BM1_Cell_AVGT_Num_ "Battery Module1 Cell 평균온도값";
CM_ SG_ 1561 BPA_BM1_Cell_AVGV_Num_ "Battery Module1 Cell 평균전압값";
CM_ SG_ 1561 BPA_BM_Volt_Total_Num_ "Battery Module1 전압값";
CM_ SG_ 1561 BPA_BMNum "Battery Module1 전압값";
CM_ SG_ 1562 BPA_CellRegs_Num_ "CellNum에 해당하는 셀 내부저항";
CM_ SG_ 1562 BPA_CellTemperature_Num_ "CellNum에 해당하는 셀 온도";
CM_ SG_ 1562 BPA_CellVoltage_Num_ "CellNum에 해당하는 셀 전압";
CM_ SG_ 1562 BPA_CellNum "전압 대상 셀 번호 (0~384)";
CM_ SG_ 1563 HMI_CanCount "HMI(출하검사) CAN 메시지 수신 시마다 내부 Count 변수 증가 (디버깅용)";
CM_ SG_ 1563 CHA_CanCount "충전기 CAN 메시지 수신 시마다 내부 Count 변수 증가 (디버깅용)";
CM_ SG_ 1563 VCU_CanCount "VCU CAN 메시지 수신 시마다 내부 Count 변수 증가 (디버깅용)";
CM_ SG_ 1563 CT_CanCount "CT 센서 CAN 메시지 수신 시마다 내부 Count 변수 증가 (디버깅용)";
CM_ SG_ 1563 BPA_ISOSPIErrCount_Num_ "CellNum에 해당하는 Slave BMS ISOSPIErrCount 값 ";
CM_ SG_ 1563 BPA_SBNum "ISOSPIErrCount 대상 Slave BMS번호 (0~384)";
CM_ SG_ 1566 BPA_Current "Current value of the battery pack measured by the BMS";
CM_ SG_ 1566 BPA_Voltage "Voltage value of the battery pack measured by the BMS";
CM_ SG_ 1566 BPA_Constant_Current "Constant Current  Charging Request from Battery System to Charger";
CM_ SG_ 1566 BPA_Constant_Voltage "Constant Voltage Charging Request from Battery System to Charger";
CM_ SG_ 1567 BPA_CHA_Start_stop "0x0 : CharStop
0x1 : CharStart";
CM_ SG_ 1567 BPA_Rly_Err "0x0 : Nor;
0x1 : Battery  Fault";
CM_ SG_ 1567 BPA_PreChar_Rly "0x0 : Battery PreChar Relay off
0x1 : Battery PreChar Relay On";
CM_ SG_ 1567 BPA_Pos_Rly "0x0 : Battery positive Relay off
0x1 : Battery positive Relay On";
CM_ SG_ 1567 BPA_Neg_Rly "0x0 : Battery negative Relay off
0x1 : Battery negative Relay On";
CM_ SG_ 1567 BPA_Protect_SOC_Under "0x0 : Nor;
0x1 : Battery  Fault";
CM_ SG_ 1567 BPA_Protect_SOC_Over "0x0 : Nor;
0x1 : Battery Fault";
CM_ SG_ 1567 BPA_Protect_OC "0x0 : Nor;
0x1 : Battery Fault";
BA_DEF_ BO_  "GenMsgCycleTime" INT 0 65535;
BA_DEF_ SG_  "GenSigStartValue" FLOAT 0 100000000000;
BA_DEF_DEF_  "GenMsgCycleTime" 0;
BA_DEF_DEF_  "GenSigStartValue" 0;
BA_ "GenMsgCycleTime" BO_ 1792 100;
BA_ "GenMsgCycleTime" BO_ 1794 1000;
BA_ "GenMsgCycleTime" BO_ 1536 100;
BA_ "GenMsgCycleTime" BO_ 812 10;
BA_ "GenMsgCycleTime" BO_ 1552 1000;
BA_ "GenSigStartValue" SG_ 1552 BPA_Capacity 4800;
BA_ "GenSigStartValue" SG_ 1552 BPA_NorVolt 480;
BA_ "GenSigStartValue" SG_ 1552 BPA_Parallel 2;
BA_ "GenSigStartValue" SG_ 1552 BPA_Serial 15;
BA_ "GenMsgCycleTime" BO_ 1553 10;
BA_ "GenMsgCycleTime" BO_ 1554 10;
BA_ "GenMsgCycleTime" BO_ 1555 100;
BA_ "GenMsgCycleTime" BO_ 1556 100;
BA_ "GenMsgCycleTime" BO_ 1557 100;
BA_ "GenMsgCycleTime" BO_ 1558 100;
BA_ "GenMsgCycleTime" BO_ 1559 100;
BA_ "GenMsgCycleTime" BO_ 1560 100;
BA_ "GenMsgCycleTime" BO_ 1561 100;
BA_ "GenMsgCycleTime" BO_ 1562 100;
BA_ "GenMsgCycleTime" BO_ 1563 100;
BA_ "GenMsgCycleTime" BO_ 1566 1000;
BA_ "GenMsgCycleTime" BO_ 1567 1000;
VAL_ 1792 HMI_Reset 1 "Reset" ;
VAL_ 1792 HMI1_CellBalaEn 1 "BalaEn" ;
VAL_ 1792 HMI1_Cell_Temps_Request 1 "TempReset" ;
VAL_ 1792 HMI1_Cell_Volt_Request 1 "VoltReqset" ;
VAL_ 1792 HMI1_COM_EN 1 "Enable" ;
VAL_ 1536 VCU_BSAHldShutdown 1 "PwrOfff" ;
VAL_ 1536 VCU_BSAReset 1 "Reset" ;
VAL_ 1554 Sys_SocSeqState 0 "SOC_STATE_IDLE" 1 "SOC_STATE_RUNNING" 2 "SOC_STATE_Save" 3 "SOC_STATE_CLEAR" ;
VAL_ 1554 SyS_RlySeqState 0 "PrtctRly_INIT" 1 "PrtctRly_STANDBY" 2 "PrtctRly_Ready" 3 "PrtctRly_RuningON" 4 "PrtctRly_RuningOFF" 5 "PrtctRly_ProtectpOFF" 6 "PrtctRly_RLYProtect" 7 "PrtctRly_CLEAR" ;
VAL_ 1554 Sys_SysSeqState 0 "INIT" 1 "STANDBY" 2 "READY" 3 "RUNING" 4 "ChargerStop 0x5 = PROTECTER" 6 "DATALOG" 7 "MANUALMode" ;
VAL_ 1554 BPA_ChargerEn 0 "DisCharEnable" 1 "CharEnable" ;
VAL_ 1554 BPA_MSD_AUX 0 "Close" 1 "Open" ;
VAL_ 1554 BPA_PreChar_Rly 0 "Rly_Off" 1 "Rly_On" ;
VAL_ 1554 BPA_Pos_Rly 0 "Rly_Off" 1 "Rly_On" ;
VAL_ 1554 BPA_Neg_Rly 0 "Rly_Off" 1 "Rly_On" ;
VAL_ 1554 BPA_Balance 0 "OFF 0x01 = ON" ;
VAL_ 1554 BPA_Protect_Status 0 "Nor" 1 "waring" 2 "Fault" 3 "Protect" ;
VAL_ 1554 BPA_Divice_Status 0 "Init" 1 "standby" 2 "Charger mode" 3 "Dischager mode" ;
VAL_ 1555 BPA_Prtct_Charger_PwrErr 0 "Nor" 1 "Protect" ;
VAL_ 1555 BPA_Prtct_Discharger_PwrErr 0 "Nor" 1 "Protect" ;
VAL_ 1555 BPA_Prtct_CTCom_Err 0 "Nor" 1 "Protect" ;
VAL_ 1555 BPA_Prtct_CharCom_Err 0 "Nor" 1 "Protect" ;
VAL_ 1555 BPA_Prtct_VCUCom_Err 0 "Nor" 1 "Protect" ;
VAL_ 1555 BPA_Prtct_ISOSPI_Err 0 "Nor" 1 "Protect" ;
VAL_ 1555 BPA_Prtct_ISORESIS_Err 0 "Nor" 1 "Protect" ;
VAL_ 1555 BPA_Prtct_MSD_Err 0 "Nor" 1 "Protect" ;
VAL_ 1555 BPA_Prtct_Rly_Err 0 "Nor" 1 "Protect" ;
VAL_ 1555 BPA_Prtct_Cell_UnbalT 0 "Nor" 1 "Protect" ;
VAL_ 1555 BPA_Prtct_Cell_UT 0 "Nor" 1 "Protect" ;
VAL_ 1555 BPA_Prtct_Cell_OT 0 "Nor" 1 "Protect" ;
VAL_ 1555 BPA_Prtct_Cell_UnbalV 0 "Nor" 1 "Protect" ;
VAL_ 1555 BPA_Prtct_Cell_UV 0 "Nor" 1 "Protect" ;
VAL_ 1555 BPA_Prtct_Cell_OV 0 "Nor" 1 "Protect" ;
VAL_ 1555 BPA_Prtct_UT 0 "Nor" 1 "Protect" ;
VAL_ 1555 BPA_Prtct_OT 0 "Nor" 1 "Protect" ;
VAL_ 1555 BPA_Prtct_UV 0 "Nor" 1 "Protect" ;
VAL_ 1555 BPA_Prtct_OV 0 "Nor" 1 "Protect" ;
VAL_ 1555 BPA_Prtct_SOC_Under 0 "Nor" 1 "Protect" ;
VAL_ 1555 BPA_Prtct_SOC_Over 0 "Nor" 1 "Protect" ;
VAL_ 1555 BPA_Prtct_OC 0 "Nor" 1 "Protect" ;
VAL_ 1555 BPA_FLT_Charger_UnBPAWR 0 "Nor" 1 "Fault" ;
VAL_ 1555 BPA_FLT_Discharger_UnBPAWR 0 "Nor" 1 "Fault" ;
VAL_ 1555 BSA_FLT_Cell_UnbalT 0 "Nor" 1 "Fault" ;
VAL_ 1555 BPA_FLT_Cell_UT 0 "Nor" 1 "Fault" ;
VAL_ 1555 BPA_FLT_Cell_OT 0 "Nor" 1 "Fault" ;
VAL_ 1555 BPA_FLT_Cell_UnbalV 0 "Nor" 1 "Fault" ;
VAL_ 1555 BPA_FLT_Cell_UV 0 "Nor" 1 "Fault" ;
VAL_ 1555 BPA_FLT_Cell_OV 0 "Nor" 1 "Fault" ;
VAL_ 1555 BPA_FLT_UT 0 "Nor" 1 "Fault" ;
VAL_ 1555 BPA_FLT_OT 0 "Nor" 1 "Fault" ;
VAL_ 1555 BPA_FLT_UV 0 "Nor" 1 "Fault" ;
VAL_ 1555 BPA_FLT_OV 0 "Nor" 1 "Fault" ;
VAL_ 1555 BPA_FLT_SOC_Under 0 "Nor" 1 "Fault" ;
VAL_ 1555 BPA_FLT_SOC_Over 0 "Nor" 1 "Fault" ;
VAL_ 1555 BPA_FLT_OC 0 "Nor" 1 "Fault" ;
VAL_ 1555 BPA_Wn_Charger_UnBPAWR 0 "Nor" 1 "Waring" ;
VAL_ 1555 BPA_Wn_Discharger_UnBPAWR 0 "Nor" 1 "Waring" ;
VAL_ 1555 BSA_Wn_Cell_UnbalT 0 "Nor" 1 "Waring" ;
VAL_ 1555 BPA_Wn_Cell_UT 0 "Nor" 1 "Waring" ;
VAL_ 1555 BPA_Wn_Cell_OT 0 "Nor" 1 "Waring" ;
VAL_ 1555 BPA_Wn_Cell_UnbalV 0 "Nor" 1 "Waring" ;
VAL_ 1555 BPA_Wn_Cell_UV 0 "Nor" 1 "Waring" ;
VAL_ 1555 BPA_Wn_Cell_OV 0 "Nor" 1 "Waring" ;
VAL_ 1555 BPA_Wn_UT 0 "Nor" 1 "Waring" ;
VAL_ 1555 BPA_Wn_OT 0 "Nor" 1 "Waring" ;
VAL_ 1555 BPA_Wn_UV 0 "Nor" 1 "Waring" ;
VAL_ 1555 BPA_Wn_OV 0 "Nor" 1 "Waring" ;
VAL_ 1555 BPA_Wn_SOC_Under 0 "Nor" 1 "Waring" ;
VAL_ 1555 BPA_Wn_SOC_Over 0 "Nor" 1 "Waring" ;
VAL_ 1555 BPA_Wn_OC 0 "Nor" 1 "Waring" ;
